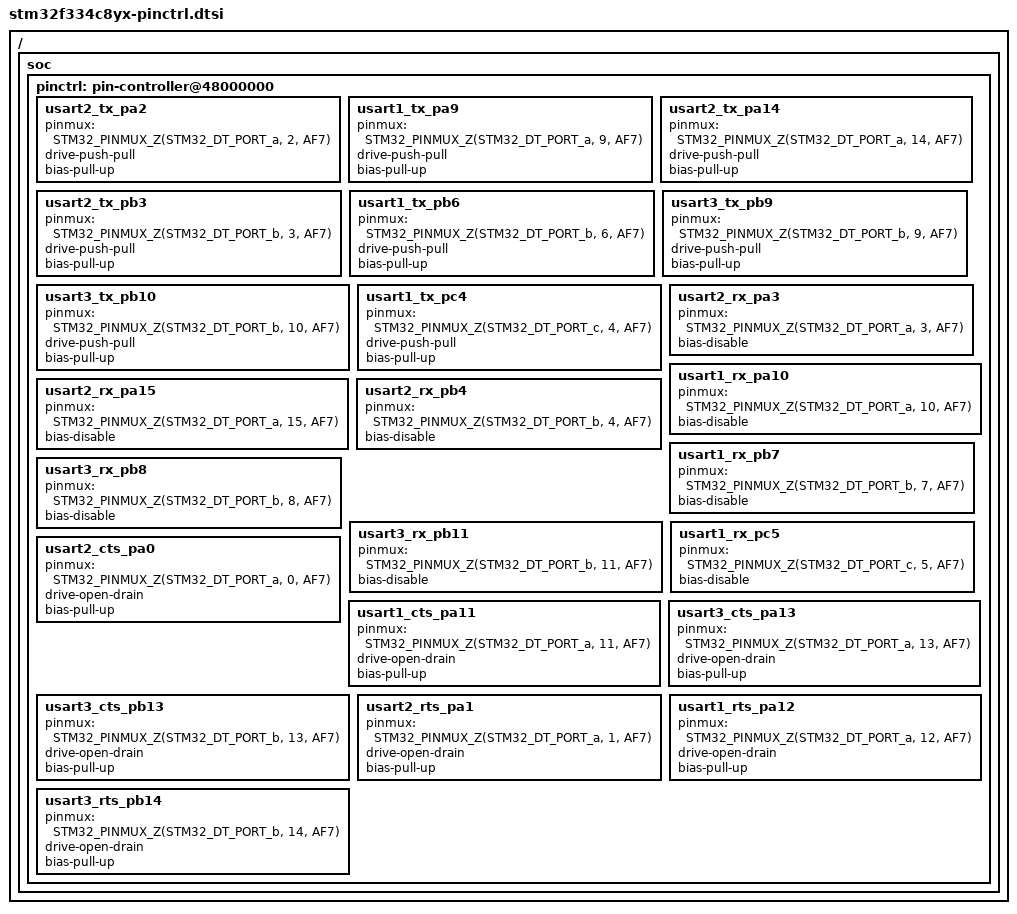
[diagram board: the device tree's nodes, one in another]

/*
 * NOTE: Autogenerated file using stm32_pinctrl_gen.py
 *
 * SPDX-License-Identifier: Apache-2.0
 */

#include <dt-bindings/pinctrl/stm32-pinctrl.h>

/ {
	soc {
		pinctrl: pin-controller@48000000 {
			/* UART_TX */
			usart2_tx_pa2: usart2_tx_pa2 {
				pinmux = <STM32_PINMUX_Z(STM32_DT_PORT_a, 2, AF7)>;
				drive-push-pull;
				bias-pull-up;
			};

			usart1_tx_pa9: usart1_tx_pa9 {
				pinmux = <STM32_PINMUX_Z(STM32_DT_PORT_a, 9, AF7)>;
				drive-push-pull;
				bias-pull-up;
			};

			usart2_tx_pa14: usart2_tx_pa14 {
				pinmux = <STM32_PINMUX_Z(STM32_DT_PORT_a, 14, AF7)>;
				drive-push-pull;
				bias-pull-up;
			};

			usart2_tx_pb3: usart2_tx_pb3 {
				pinmux = <STM32_PINMUX_Z(STM32_DT_PORT_b, 3, AF7)>;
				drive-push-pull;
				bias-pull-up;
			};

			usart1_tx_pb6: usart1_tx_pb6 {
				pinmux = <STM32_PINMUX_Z(STM32_DT_PORT_b, 6, AF7)>;
				drive-push-pull;
				bias-pull-up;
			};

			usart3_tx_pb9: usart3_tx_pb9 {
				pinmux = <STM32_PINMUX_Z(STM32_DT_PORT_b, 9, AF7)>;
				drive-push-pull;
				bias-pull-up;
			};

			usart3_tx_pb10: usart3_tx_pb10 {
				pinmux = <STM32_PINMUX_Z(STM32_DT_PORT_b, 10, AF7)>;
				drive-push-pull;
				bias-pull-up;
			};

			usart1_tx_pc4: usart1_tx_pc4 {
				pinmux = <STM32_PINMUX_Z(STM32_DT_PORT_c, 4, AF7)>;
				drive-push-pull;
				bias-pull-up;
			};


			/* UART_RX */
			usart2_rx_pa3: usart2_rx_pa3 {
				pinmux = <STM32_PINMUX_Z(STM32_DT_PORT_a, 3, AF7)>;
				bias-disable;
			};

			usart1_rx_pa10: usart1_rx_pa10 {
				pinmux = <STM32_PINMUX_Z(STM32_DT_PORT_a, 10, AF7)>;
				bias-disable;
			};

			usart2_rx_pa15: usart2_rx_pa15 {
				pinmux = <STM32_PINMUX_Z(STM32_DT_PORT_a, 15, AF7)>;
				bias-disable;
			};

			usart2_rx_pb4: usart2_rx_pb4 {
				pinmux = <STM32_PINMUX_Z(STM32_DT_PORT_b, 4, AF7)>;
				bias-disable;
			};

			usart1_rx_pb7: usart1_rx_pb7 {
				pinmux = <STM32_PINMUX_Z(STM32_DT_PORT_b, 7, AF7)>;
				bias-disable;
			};

			usart3_rx_pb8: usart3_rx_pb8 {
				pinmux = <STM32_PINMUX_Z(STM32_DT_PORT_b, 8, AF7)>;
				bias-disable;
			};

			usart3_rx_pb11: usart3_rx_pb11 {
				pinmux = <STM32_PINMUX_Z(STM32_DT_PORT_b, 11, AF7)>;
				bias-disable;
			};

			usart1_rx_pc5: usart1_rx_pc5 {
				pinmux = <STM32_PINMUX_Z(STM32_DT_PORT_c, 5, AF7)>;
				bias-disable;
			};


			/* UART_CTS */
			usart2_cts_pa0: usart2_cts_pa0 {
				pinmux = <STM32_PINMUX_Z(STM32_DT_PORT_a, 0, AF7)>;
				drive-open-drain;
				bias-pull-up;
			};

			usart1_cts_pa11: usart1_cts_pa11 {
				pinmux = <STM32_PINMUX_Z(STM32_DT_PORT_a, 11, AF7)>;
				drive-open-drain;
				bias-pull-up;
			};

			usart3_cts_pa13: usart3_cts_pa13 {
				pinmux = <STM32_PINMUX_Z(STM32_DT_PORT_a, 13, AF7)>;
				drive-open-drain;
				bias-pull-up;
			};

			usart3_cts_pb13: usart3_cts_pb13 {
				pinmux = <STM32_PINMUX_Z(STM32_DT_PORT_b, 13, AF7)>;
				drive-open-drain;
				bias-pull-up;
			};


			/* UART_RTS */
			usart2_rts_pa1: usart2_rts_pa1 {
				pinmux = <STM32_PINMUX_Z(STM32_DT_PORT_a, 1, AF7)>;
				drive-open-drain;
				bias-pull-up;
			};

			usart1_rts_pa12: usart1_rts_pa12 {
				pinmux = <STM32_PINMUX_Z(STM32_DT_PORT_a, 12, AF7)>;
				drive-open-drain;
				bias-pull-up;
			};

			usart3_rts_pb14: usart3_rts_pb14 {
				pinmux = <STM32_PINMUX_Z(STM32_DT_PORT_b, 14, AF7)>;
				drive-open-drain;
				bias-pull-up;
			};

		};
	};
};
